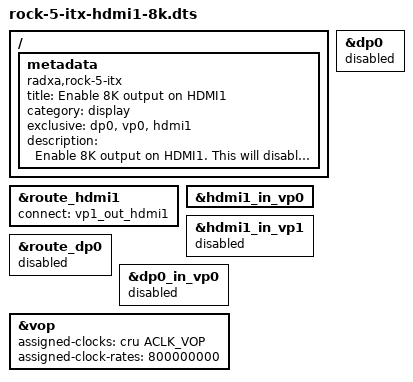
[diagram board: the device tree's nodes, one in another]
/dts-v1/;
/plugin/;
#include <dt-bindings/clock/rk3588-cru.h>

/ {
	metadata {
		title = "Enable 8K output on HDMI1";
		compatible = "radxa,rock-5-itx";
		category = "display";
		exclusive = "dp0", "vp0", "hdmi1";
		description = "Enable 8K output on HDMI1.
This will disable DP0.";
	};
};

&route_hdmi1 {
	connect = <&vp1_out_hdmi1>;
	status = "okay";
};

&hdmi1_in_vp0 {
	status = "okay";
};

&hdmi1_in_vp1 {
	status = "disabled";
};

&route_dp0 {
	status = "disabled";
};

&dp0 {
	status = "disabled";
};

&dp0_in_vp0 {
	status = "disabled";
};

&vop {
	assigned-clocks = <&cru ACLK_VOP>;
	assigned-clock-rates = <800000000>;
};
